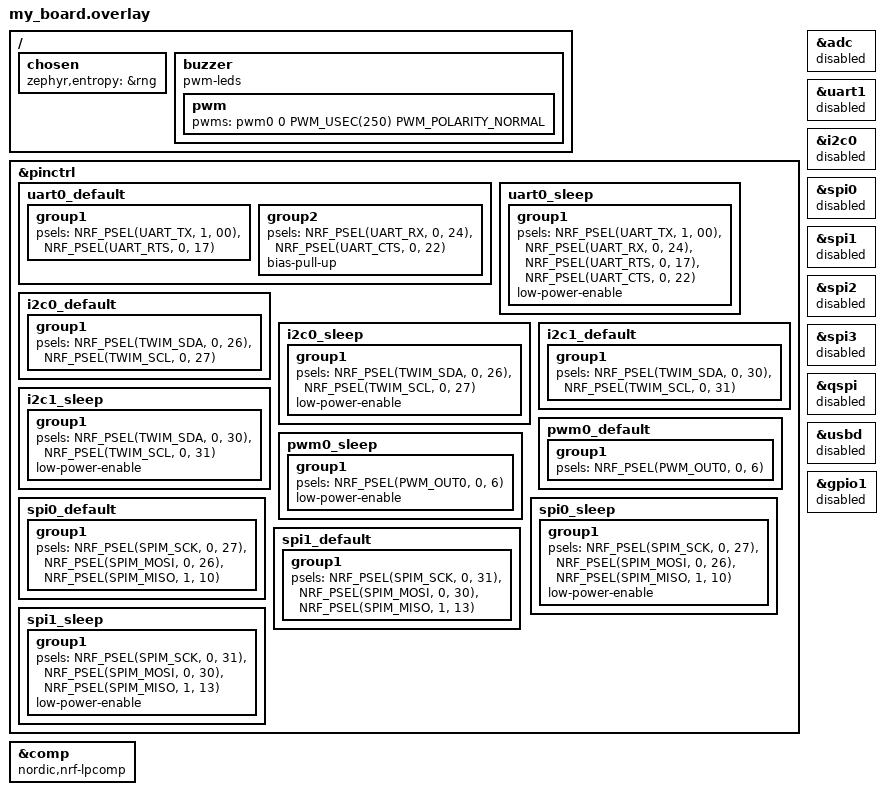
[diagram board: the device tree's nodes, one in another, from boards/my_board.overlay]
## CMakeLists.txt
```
list(APPEND OVERLAY_CONFIG "dns.conf")
list(APPEND OVERLAY_CONFIG "secret.conf")
list(APPEND OVERLAY_CONFIG "thread-sed.conf")

cmake_minimum_required(VERSION 3.20.0)
list(APPEND BOARD_ROOT ${CMAKE_CURRENT_SOURCE_DIR})
find_package(Zephyr REQUIRED HINTS $ENV{ZEPHYR_BASE})

execute_process(COMMAND git describe
                WORKING_DIRECTORY ${CMAKE_CURRENT_SOURCE_DIR}
                OUTPUT_VARIABLE GIT_DESCRIBE
                ERROR_QUIET)
string(STRIP "${GIT_DESCRIBE}" GIT_DESCRIBE)
STRING(REGEX MATCH "[0-9]+\\.[0-9]+\\.[0-9]+"
       VERSION "${GIT_DESCRIBE}")

project(app LANGUAGES C VERSION ${VERSION})


configure_file(app_version.h.in ${CMAKE_BINARY_DIR}/app/include/app_version.h)
zephyr_include_directories(
    ${CMAKE_BINARY_DIR}/app/include
)
target_include_directories(app PRIVATE ${CMAKE_BINARY_DIR}/app/include src)

target_sources(app PRIVATE
        src/buzzer.c
        src/main.c)
```

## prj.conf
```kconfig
CONFIG_HEAP_MEM_POOL_SIZE=2048

CONFIG_PM_DEVICE=y
CONFIG_POWEROFF=y

CONFIG_MY_MODULE_BASE_RESET=y
CONFIG_MY_MODULE_BASE_UID=y

CONFIG_MY_MODULE_BASE_HOME_ASSISTANT=y
CONFIG_MY_MODULE_BASE_HA_DEVICE_NAME="Leak Detector"
CONFIG_MY_MODULE_BASE_HA_DEV_TYPE_LEAK_DETECTOR=y
CONFIG_MY_MODULE_BASE_HA_MQTT_SERVER_HOSTNAME="home.home.arpa"

CONFIG_MAIN_STACK_SIZE=4096
CONFIG_SYSTEM_WORKQUEUE_STACK_SIZE=2048
CONFIG_LOG_BUFFER_SIZE=16384

# This board does not have the inductor.
# Cannot enable the DCDC converter.
CONFIG_BOARD_ENABLE_DCDC=n

CONFIG_THREAD_NAME=y
CONFIG_THREAD_ANALYZER=y

CONFIG_LOG_SPEED=y
CONFIG_LOG=y
```

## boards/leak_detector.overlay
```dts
// &pwm0 {
// 	compatible = "nordic,nrf-pwm-seq";
// 	status = "okay";
// 	pinctrl-0 = <&pwm0_default>;
// 	pinctrl-1 = <&pwm0_sleep>;
// 	pinctrl-names = "default", "sleep";
// };
```

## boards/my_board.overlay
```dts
/* Copyright (c) 2020 Nordic Semiconductor ASA
 *
 * SPDX-License-Identifier: LicenseRef-Nordic-5-Clause
 */

/ {
	/*
	* In some default configurations within the nRF Connect SDK,
	* e.g. on nRF52840, the chosen zephyr,entropy node is &cryptocell.
	* This devicetree overlay ensures that default is overridden wherever it
	* is set, as this application uses the RNG node for entropy exclusively.
	*/
	chosen {
		zephyr,entropy = &rng;
	};
	buzzer {
		compatible = "pwm-leds";
		pwm {
			pwms = <&pwm0 0 PWM_USEC(250) PWM_POLARITY_NORMAL>;
		};
	};
};
&pinctrl {
	uart0_default: uart0_default {
		group1 {
			psels = <NRF_PSEL(UART_TX, 1, 00)>,
				<NRF_PSEL(UART_RTS, 0, 17)>;
		};
		group2 {
			psels = <NRF_PSEL(UART_RX, 0, 24)>,
				<NRF_PSEL(UART_CTS, 0, 22)>;
			bias-pull-up;
		};
	};

	uart0_sleep: uart0_sleep {
		group1 {
			psels = <NRF_PSEL(UART_TX, 1, 00)>,
				<NRF_PSEL(UART_RX, 0, 24)>,
				<NRF_PSEL(UART_RTS, 0, 17)>,
				<NRF_PSEL(UART_CTS, 0, 22)>;
			low-power-enable;
		};
	};

	i2c0_default: i2c0_default {
		group1 {
			psels = <NRF_PSEL(TWIM_SDA, 0, 26)>,
				<NRF_PSEL(TWIM_SCL, 0, 27)>;
		};
	};

	i2c0_sleep: i2c0_sleep {
		group1 {
			psels = <NRF_PSEL(TWIM_SDA, 0, 26)>,
				<NRF_PSEL(TWIM_SCL, 0, 27)>;
			low-power-enable;
		};
	};

	i2c1_default: i2c1_default {
		group1 {
			psels = <NRF_PSEL(TWIM_SDA, 0, 30)>,
				<NRF_PSEL(TWIM_SCL, 0, 31)>;
		};
	};

	i2c1_sleep: i2c1_sleep {
		group1 {
			psels = <NRF_PSEL(TWIM_SDA, 0, 30)>,
				<NRF_PSEL(TWIM_SCL, 0, 31)>;
			low-power-enable;
		};
	};

	pwm0_default: pwm0_default {
		group1 {
			psels = <NRF_PSEL(PWM_OUT0, 0, 6)>;
		};
	};

	pwm0_sleep: pwm0_sleep {
		group1 {
			psels = <NRF_PSEL(PWM_OUT0, 0, 6)>;
			low-power-enable;
		};
	};

	spi0_default: spi0_default {
		group1 {
			psels = <NRF_PSEL(SPIM_SCK, 0, 27)>,
				<NRF_PSEL(SPIM_MOSI, 0, 26)>,
				<NRF_PSEL(SPIM_MISO, 1, 10)>;
		};
	};

	spi0_sleep: spi0_sleep {
		group1 {
			psels = <NRF_PSEL(SPIM_SCK, 0, 27)>,
				<NRF_PSEL(SPIM_MOSI, 0, 26)>,
				<NRF_PSEL(SPIM_MISO, 1, 10)>;
			low-power-enable;
		};
	};

	spi1_default: spi1_default {
		group1 {
			psels = <NRF_PSEL(SPIM_SCK, 0, 31)>,
				<NRF_PSEL(SPIM_MOSI, 0, 30)>,
				<NRF_PSEL(SPIM_MISO, 1, 13)>;
		};
	};

	spi1_sleep: spi1_sleep {
		group1 {
			psels = <NRF_PSEL(SPIM_SCK, 0, 31)>,
				<NRF_PSEL(SPIM_MOSI, 0, 30)>,
				<NRF_PSEL(SPIM_MISO, 1, 13)>;
			low-power-enable;
		};
	};

};
&adc {
	status = "disabled";
};
&comp {
	compatible = "nordic,nrf-lpcomp";
	status = "okay";
};
&uart1 {
	status = "disabled";
};
//&pwm0 {
//	status = "disabled";
//};
&i2c0 {
	status = "disabled";
};
&spi0 {
	status = "disabled";
};
&spi1 {
	status = "disabled";
};
&spi2 {
	status = "disabled";
};
&spi3 {
	status = "disabled";
};
&qspi {
	status = "disabled";
};
&usbd {
	status = "disabled";
};
&gpio1 {
	status = "disabled";
};
```

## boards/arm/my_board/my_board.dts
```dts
/*
 * Copyright (c) 2018 Nordic Semiconductor ASA
 * Copyright (c) 2017 Linaro Limited
 *
 * SPDX-License-Identifier: Apache-2.0
 */

/dts-v1/;
#include <nordic/nrf52840_qiaa.dtsi>
#include "my_board-pinctrl.dtsi"

/ {
	model = "My Board";
	compatible = "gervais,my-board";

	chosen {
		zephyr,console = &uart0;
		zephyr,shell-uart = &uart0;
		zephyr,uart-mcumgr = &uart0;
		zephyr,bt-mon-uart = &uart0;
		zephyr,bt-c2h-uart = &uart0;
		zephyr,sram = &sram0;
		zephyr,flash = &flash0;
		zephyr,code-partition = &slot0_partition;
	};

	// leds {
	// 	compatible = "gpio-leds";
	// 	led0_green: led_0 {
	// 		gpios = <&gpio0 6 GPIO_ACTIVE_LOW>;
	// 		label = "Green LED 0";
	// 	};
	// 	led1_red: led_1 {
	// 		gpios = <&gpio0 8 GPIO_ACTIVE_LOW>;
	// 		label = "Red LED 1";
	// 	};
	// 	led1_green: led_2 {
	// 		gpios = <&gpio1 9 GPIO_ACTIVE_LOW>;
	// 		label = "Green LED 1";
	// 	};
	// 	led1_blue: led_3 {
	// 		gpios = <&gpio0 12 GPIO_ACTIVE_LOW>;
	// 		label = "Blue LED 1";
	// 	};
	// };

	// pwmleds {
	// 	compatible = "pwm-leds";
	// 	red_pwm_led: pwm_led_0 {
	// 		pwms = <&pwm0 0 PWM_MSEC(20) PWM_POLARITY_INVERTED>;
	// 	};
	// 	green_pwm_led: pwm_led_1 {
	// 		pwms = <&pwm0 1 PWM_MSEC(20) PWM_POLARITY_INVERTED>;
	// 	};
	// 	blue_pwm_led: pwm_led_2 {
	// 		pwms = <&pwm0 2 PWM_MSEC(20) PWM_POLARITY_INVERTED>;
	// 	};
	// };

	// buttons {
	// 	compatible = "gpio-keys";
	// 	button0: button_0 {
	// 		gpios = <&gpio1 6 (GPIO_PULL_UP | GPIO_ACTIVE_LOW)>;
	// 		label = "Push button switch 0";
	// 	};
	// };

	/* These aliases are provided for compatibility with samples */
	aliases {
		// sw0 = &button0;
		// led0 = &led0_green;
		// led1 = &led1_red;
		// led2 = &led1_green;
		// led3 = &led1_blue;
		// led0-green = &led0_green;
		// led1-red   = &led1_red;
		// led1-green = &led1_green;
		// led1-blue  = &led1_blue;
		// pwm-led0 = &red_pwm_led;
		// pwm-led1 = &green_pwm_led;
		// pwm-led2 = &blue_pwm_led;
		// red-pwm-led = &red_pwm_led;
		// green-pwm-led = &green_pwm_led;
		// blue-pwm-led = &blue_pwm_led;
		// mcuboot-button0 = &button0;
		// mcuboot-led0 = &led0_green;
		watchdog0 = &wdt0;
	};
};

&adc {
	status = "okay";
};

&gpiote {
	status = "okay";
};

&gpio0 {
	status = "okay";
};

&gpio1 {
	status = "okay";
};

&uart0 {
	compatible = "nordic,nrf-uarte";
	status = "okay";
	current-speed = <115200>;
	pinctrl-0 = <&uart0_default>;
	pinctrl-1 = <&uart0_sleep>;
	pinctrl-names = "default", "sleep";
};

&i2c0 {
	compatible = "nordic,nrf-twi";
	status = "okay";
	pinctrl-0 = <&i2c0_default>;
	pinctrl-1 = <&i2c0_sleep>;
	pinctrl-names = "default", "sleep";
};

&i2c1 {
	compatible = "nordic,nrf-twi";
	/* Cannot be used together with spi1. */
	/* status = "okay"; */
	pinctrl-0 = <&i2c1_default>;
	pinctrl-1 = <&i2c1_sleep>;
	pinctrl-names = "default", "sleep";
};

&pwm0 {
	status = "okay";
	pinctrl-0 = <&pwm0_default>;
	pinctrl-1 = <&pwm0_sleep>;
	pinctrl-names = "default", "sleep";
};

/*
 * By default, not adding all available SPI instances (spi2, spi3) due to
 * limited GPIOs available on dongle board.
 */
&spi0 {
	compatible = "nordic,nrf-spi";
	/* Cannot be used together with i2c0. */
	/* status = "okay"; */
	pinctrl-0 = <&spi0_default>;
	pinctrl-1 = <&spi0_sleep>;
	pinctrl-names = "default", "sleep";
};

&spi1 {
	compatible = "nordic,nrf-spi";
	status = "okay";
	pinctrl-0 = <&spi1_default>;
	pinctrl-1 = <&spi1_sleep>;
	pinctrl-names = "default", "sleep";
};

/* Include flash partition table.
 * Two partition tables are available:
 * fstab-stock		-compatible with Nordic nRF5 bootloader, default
 * fstab-debugger	-to use an external debugger, w/o the nRF5 bootloader
 */
#include "fstab-debugger.dts"

zephyr_udc0: &usbd {
	compatible = "nordic,nrf-usbd";
	status = "okay";
};
```

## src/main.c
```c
#include <zephyr/drivers/pwm.h>
#include <zephyr/kernel.h>
#include <zephyr/pm/device.h>
#include <zephyr/pm/pm.h>
#include <zephyr/pm/policy.h>
#include <zephyr/sys/poweroff.h>

#include <hal/nrf_power.h>
#include <nrfx_lpcomp.h>

#include <zephyr/logging/log.h>
LOG_MODULE_REGISTER(main, LOG_LEVEL_DBG);

#include <app_version.h>
#include <mymodule/base/ha.h>
#include <mymodule/base/mqtt.h>
#include <mymodule/base/openthread.h>
#include <mymodule/base/reset.h>
#include <mymodule/base/uid.h>

#include "buzzer.h"


#define ALARM_TIME_SEC		60
#define HA_NUMBER_OF_RETRIES	3
#define HA_RETRY_DELAY_SECONDS	10


static struct ha_sensor leak_detected_sensor = {
	.type = HA_BINARY_SENSOR_TYPE,
	.name = "Leak",
	.device_class = "problem",
	.retain = true,
};


static void comparator_handler(nrf_lpcomp_event_t event)
{
	LOG_INF("COMP event");
}

static int system_off(void)
{
	int ret;
	const struct device *cons = DEVICE_DT_GET(DT_CHOSEN(zephyr_console));

	LOG_INF("Entering system off");

	ret = pm_device_action_run(cons, PM_DEVICE_ACTION_SUSPEND);
	if (ret < 0) {
		LOG_ERR("Could not suspend console (%d)", ret);
		return -1;
	}

	sys_poweroff();

	return 0;
}

int main(void)
{
	uint32_t reset_cause;
	int ret;

	nrfx_err_t err;
	nrfx_lpcomp_config_t lpcomp_config = {
	    .reference = NRF_LPCOMP_REF_SUPPLY_6_8,
	    .detection = NRF_LPCOMP_DETECT_DOWN,
	    NRFX_COND_CODE_1(LPCOMP_FEATURE_HYST_PRESENT, (.hyst = NRF_LPCOMP_HYST_NOHYST,), ())
	    .input  = (nrf_lpcomp_input_t)NRF_LPCOMP_INPUT_2,
	    .interrupt_priority = NRFX_LPCOMP_DEFAULT_CONFIG_IRQ_PRIORITY
	};
	const struct pwm_dt_spec buzzer_dt_spec = PWM_DT_SPEC_GET(DT_PATH(buzzer));


	LOG_INF("\n\n🚀 MAIN START (%s) 🚀\n", APP_VERSION_FULL);

	reset_cause = show_and_clear_reset_cause();

	if (!device_is_ready(buzzer_dt_spec.dev)) {
		printk("%s: device not ready.\n", buzzer_dt_spec.dev->name);
		return 1;
	}

	ret = buzzer_init(&buzzer_dt_spec);
	if (ret < 0) {
		LOG_ERR("Could not initialize buzzer");
		return 1;
	}

	// Do only the bare minimum to start the alarm if required.
	// This is the priority.
	if (is_reset_cause_lpcomp(reset_cause)) {
		buzzer_alarm(ALARM_TIME_SEC);
	}

	ret = openthread_my_start();
	if (ret < 0) {
		LOG_ERR("Could not start openthread");
		return ret;
	}

	ret = uid_init();
	if (ret < 0) {
		LOG_ERR("Could not init uid module");
		return ret;
	}

	ret = uid_generate_unique_id(leak_detected_sensor.unique_id,
				     sizeof(leak_detected_sensor.unique_id),
				     "nrf52840", "leak",
				     uid_get_device_id());
	if (ret < 0) {
		LOG_ERR("Could not generate leak sensor unique id");
		return ret;
	}

	LOG_INF("💤 waiting for openthread to be ready");
	openthread_wait_for_ready();
	// Something else is not ready, not sure what
	k_sleep(K_MSEC(100));

	bool inhibit_discovery = is_reset_cause_lpcomp(reset_cause);
	bool enable_last_will = false;
	ha_start(uid_get_device_id(), inhibit_discovery, enable_last_will);

	// On the alert path, this has not way to fail other than ENOMEM
	ha_register_sensor_retry(&leak_detected_sensor,
				 HA_NUMBER_OF_RETRIES,
				 HA_RETRY_DELAY_SECONDS,
				 0);

	ha_set_binary_sensor_state(&leak_detected_sensor,
				   is_reset_cause_lpcomp(reset_cause));

	if (is_reset_cause_lpcomp(reset_cause)) {
		// Retry for about 3h, this is the last thing we will do anyway
		ha_send_binary_sensor_retry(&leak_detected_sensor,
				    	    11, // Last after about 3h
					    HA_RETRY_DELAY_SECONDS,
					    (HA_RETRY_EXP_BACKOFF |
					     HA_RETRY_WAIT_PUBACK));
	}
	else {
		// We set the device online a little after sensor
		// registrations so HA gets time to process the sensor
		// registrations first before setting the entities online
		LOG_INF("💤 waiting for HA to process registration");
		k_sleep(K_SECONDS(3));

		ha_set_online_retry(HA_NUMBER_OF_RETRIES,
				    HA_RETRY_DELAY_SECONDS,
				    HA_RETRY_NO_FLAGS);

		ha_send_binary_sensor_retry(&leak_detected_sensor,
				    	    HA_NUMBER_OF_RETRIES,
					    HA_RETRY_DELAY_SECONDS,
					    HA_RETRY_NO_FLAGS);

		// Arm the detector
		err = nrfx_lpcomp_init(&lpcomp_config, comparator_handler);
		if (err != NRFX_SUCCESS) {
			LOG_ERR("nrfx_comp_init error: %08x", err);
			return 1;
		}

		IRQ_CONNECT(COMP_LPCOMP_IRQn,
			    IRQ_PRIO_LOWEST,
			    nrfx_isr, nrfx_lpcomp_irq_handler, 0);

		nrfx_lpcomp_enable();

		LOG_INF("🆗 initialized");

		LOG_INF("Playing detector ready sound");
		// smb3_sound_1up();
		smb3_sound_enter_world();
		// smd3_sound_game_over();
		// smb2_sound_game_over();
		// smb2_main_theme();
	}

	while (buzzer_is_running(&buzzer_dt_spec)) {
		LOG_INF("Waiting for buzzer to finish");
		k_sleep(K_SECONDS(1));
	}

	system_off();

	return 0;
}
```

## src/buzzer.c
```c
#include <zephyr/drivers/pwm.h>
#include <zephyr/kernel.h>

#include <zephyr/logging/log.h>
// LOG_MODULE_REGISTER(buzzer, LOG_LEVEL_DBG);
LOG_MODULE_REGISTER(buzzer, LOG_LEVEL_INF);

#include <nrfx_pwm.h>

#include "music_notes.h"


#define ALARM_PWM_BASE_CLOCK	16000000.0f
#define ALARM_PWM_PRESCALER	1.0f
#define ALARM_PWM_CLOCK_HZ	(ALARM_PWM_BASE_CLOCK / ALARM_PWM_PRESCALER)

#define ALARM_DESIRED_FREQ_HZ	4000.0f
#define ALARM_TOP_VALUE		((1.0f/ALARM_DESIRED_FREQ_HZ) / (1.0f/ALARM_PWM_CLOCK_HZ))

#define ALARM_PERIOD_SEC 	0.500f
#define ALARM_VALUE_REPEAT	((ALARM_PERIOD_SEC / 2.0f) / (1.0f/ALARM_DESIRED_FREQ_HZ))

#define MAX_NUMBER_OF_NOTES	32


/*
 * Although we send a sequence of a single note at a time, `note_value[]` is of
 * size `2` because the STOP event is triggered when the last value of the
 * sequence is loaded i.e. before the value is repeated.
 * Without this second dummy value, only the first period of the note would be
 * played.
 * 
 * See `NRFX_PWM_FLAG_STOP` definition for more information.
 * 
 * > The STOP task is triggered when the last value of the final sequence is
 * loaded from RAM, and the peripheral stops at the end of the current PWM period.
 * For sequences with configured repeating of duty cycle values, this might
 * result in less than the requested number of repeats of the last value.
 */
struct sound_effect_playback {
	uint16_t note_value[2];
	uint16_t notes_base_clock[MAX_NUMBER_OF_NOTES];
	uint16_t notes_top_value[MAX_NUMBER_OF_NOTES];
	uint16_t notes_value[MAX_NUMBER_OF_NOTES];
	uint32_t notes_repeat_value[MAX_NUMBER_OF_NOTES];
	int number_of_notes;
	int note_to_play;
};

enum mode {
	ALARM,
	SOUND_EFFECT,
};

struct buzzer {
	nrfx_pwm_t *pwm_instance;
	enum mode mode;
	struct sound_effect_playback sep;
	uint16_t alarm_sequence_values[2];
};


static void play_next_note(struct buzzer *buzzer);


static void pwm_handler(nrfx_pwm_evt_type_t event_type, void *p_context)
{
	struct buzzer *buzzer = p_context;
	struct sound_effect_playback *sep = &buzzer->sep;

	LOG_DBG("pwm_handler (%d)", event_type);

	if (event_type == NRFX_PWM_EVT_STOPPED) {
		if (buzzer->mode == SOUND_EFFECT
		    && sep->note_to_play < sep->number_of_notes) {
			play_next_note(buzzer);
		}
	}
}


static struct buzzer buzzer  = {
	.alarm_sequence_values = {
		ALARM_TOP_VALUE / 2,	// 50% PWM
		ALARM_TOP_VALUE,	// 0%
	},
};


static int add_note(struct sound_effect_playback *sep,
		     float note, float note_duration_ms)
{
	int note_index = sep->number_of_notes;
	uint8_t clk_divider;
	uint32_t top_value; // 32bit so we can verify if is fits in 15bit
	uint32_t pwm_clock;

	LOG_DBG("-----------------");

	LOG_DBG("note: %d", (int)note);

	if (note == 0) {
		pwm_clock = 16000000;
		clk_divider = 0;
		top_value = 16000; // Gives 1ms per pwm period
	}
	else {
		for (clk_divider = 0; clk_divider < 8; clk_divider++) {
			pwm_clock = 16000000 >> clk_divider;
			LOG_DBG("pwm_clock: %d", pwm_clock);

			top_value = (1.0f / note) / (1.0f / pwm_clock);
			LOG_DBG("top_value: %d", top_value);

			if (top_value < (UINT16_MAX >> 1)) {
				break;
			}
		}

		if (clk_divider == 8) {
			LOG_ERR("Could not find a suitable PWM divider");
			return -EINVAL;
		}
	}

	sep->notes_base_clock[note_index] = clk_divider;
	sep->notes_top_value[note_index] = top_value;

	if (note == 0) {
		sep->notes_value[note_index] = top_value;
	}
	else {
		sep->notes_value[note_index] = top_value / 2.0f;
	}

	sep->notes_repeat_value[note_index] = (
		(note_duration_ms / 1000.0f)
		/ ((1.0f / pwm_clock) * top_value)
	);

	LOG_DBG("notes_repeat_value: %d", sep->notes_repeat_value[note_index]);

	sep->number_of_notes++;

	return 0;
}

static void play_next_note(struct buzzer *buzzer)
{
	struct sound_effect_playback *sep = &buzzer->sep;

	LOG_DBG("🎹 Playing note %d", sep->note_to_play);
	LOG_DBG("├── note base clock %d", sep->notes_base_clock[sep->note_to_play]);
	LOG_DBG("├── note top value %d", sep->notes_top_value[sep->note_to_play]);
	LOG_DBG("├── note value %d", sep->notes_value[sep->note_to_play]);
	LOG_DBG("└── note repeat %d", sep->notes_repeat_value[sep->note_to_play]);

	sep->note_value[0] = sep->notes_value[sep->note_to_play];

	nrf_pwm_configure(buzzer->pwm_instance->p_reg,
			  sep->notes_base_clock[sep->note_to_play],
			  NRF_PWM_MODE_UP,
			  sep->notes_top_value[sep->note_to_play]);

	nrf_pwm_sequence_t note_sequence = {
		.values.p_raw = (uint16_t *)&sep->note_value,
		.length = ARRAY_SIZE(sep->note_value),
		.repeats = sep->notes_repeat_value[sep->note_to_play],
	};

	nrfx_pwm_simple_playback(buzzer->pwm_instance,
				 &note_sequence,
				 1,
				 NRFX_PWM_FLAG_STOP);

	sep->note_to_play++;
}

void smb3_sound_1up(void)
{
	buzzer.mode = SOUND_EFFECT;

	buzzer.sep.note_to_play = 0;
	buzzer.sep.number_of_notes = 0;

	add_note(&buzzer.sep, NOTE_E6, 135);
	add_note(&buzzer.sep, NOTE_G6, 135);
	add_note(&buzzer.sep, NOTE_E7, 135);
	add_note(&buzzer.sep, NOTE_C7, 135);
	add_note(&buzzer.sep, NOTE_D7, 135);
	add_note(&buzzer.sep, NOTE_G7, 135);

	play_next_note(&buzzer);
}

void smb3_sound_enter_world(void)
{
	buzzer.mode = SOUND_EFFECT;

	buzzer.sep.note_to_play = 0;
	buzzer.sep.number_of_notes = 0;

	add_note(&buzzer.sep, NOTE_FS8, 66);
	add_note(&buzzer.sep, NOTE_DS8, 66);
	add_note(&buzzer.sep, NOTE_C8, 66);
	add_note(&buzzer.sep, NOTE_A7, 66);
	add_note(&buzzer.sep, NOTE_G7, 66);
	add_note(&buzzer.sep, NOTE_E7, 66);
	add_note(&buzzer.sep, NOTE_CS7, 66);
	add_note(&buzzer.sep, NOTE_A6, 66);
	add_note(&buzzer.sep, NOTE_G6, 66);
	add_note(&buzzer.sep, NOTE_E6, 66);
	add_note(&buzzer.sep, NOTE_CS6, 66);
	add_note(&buzzer.sep, NOTE_A5, 300);

	play_next_note(&buzzer);
}

void smd3_sound_game_over(void)
{
	buzzer.mode = SOUND_EFFECT;

	buzzer.sep.note_to_play = 0;
	buzzer.sep.number_of_notes = 0;

	add_note(&buzzer.sep, NOTE_G5, 150);
	add_note(&buzzer.sep, 0, 50);
	add_note(&buzzer.sep, NOTE_G5, 150);
	add_note(&buzzer.sep, 0, 50);
	add_note(&buzzer.sep, NOTE_G5, 150);
	add_note(&buzzer.sep, 0, 50);
	add_note(&buzzer.sep, NOTE_D6, 400);
	add_note(&buzzer.sep, NOTE_C6, 200);
	add_note(&buzzer.sep, NOTE_A5, 200);
	add_note(&buzzer.sep, NOTE_F5, 200);
	add_note(&buzzer.sep, NOTE_AS5, 200);
	add_note(&buzzer.sep, 0, 400);
	add_note(&buzzer.sep, NOTE_CS5, 200);
	add_note(&buzzer.sep, NOTE_D5, 150);
	add_note(&buzzer.sep, 0, 50);
	add_note(&buzzer.sep, NOTE_G4, 200);

	play_next_note(&buzzer);
}

void smb2_sound_game_over(void)
{
	buzzer.mode = SOUND_EFFECT;

	buzzer.sep.note_to_play = 0;
	buzzer.sep.number_of_notes = 0;

	add_note(&buzzer.sep, NOTE_G6, 100);
	add_note(&buzzer.sep, NOTE_A6, 100);
	add_note(&buzzer.sep, NOTE_C7, 100);
	add_note(&buzzer.sep, 0, 50);
	add_note(&buzzer.sep, NOTE_G5, 100);
	add_note(&buzzer.sep, NOTE_A5, 100);
	add_note(&buzzer.sep, NOTE_C6, 100);
	add_note(&buzzer.sep, 0, 50);
	add_note(&buzzer.sep, NOTE_G4, 100);
	add_note(&buzzer.sep, NOTE_A4, 100);
	add_note(&buzzer.sep, NOTE_C5, 100);
	add_note(&buzzer.sep, 0, 100);
	add_note(&buzzer.sep, NOTE_F4, 100);
	add_note(&buzzer.sep, 0, 100);
	add_note(&buzzer.sep, NOTE_E4, 150);

	play_next_note(&buzzer);
}

void smb2_main_theme(void)
{
	buzzer.mode = SOUND_EFFECT;

	buzzer.sep.note_to_play = 0;
	buzzer.sep.number_of_notes = 0;

	add_note(&buzzer.sep, NOTE_G6, 100);
	add_note(&buzzer.sep, NOTE_FS6, 100);
	add_note(&buzzer.sep, 0, 50);
	add_note(&buzzer.sep, NOTE_F6, 100);
	add_note(&buzzer.sep, NOTE_D6, 100);
	add_note(&buzzer.sep, 0, 50);
	add_note(&buzzer.sep, NOTE_B5, 100);
	add_note(&buzzer.sep, NOTE_A5, 100);
	add_note(&buzzer.sep, 0, 50);
	add_note(&buzzer.sep, NOTE_GS5, 100);
	add_note(&buzzer.sep, NOTE_G5, 100);
	add_note(&buzzer.sep, 0, 150);
	add_note(&buzzer.sep, NOTE_G6, 100);
	add_note(&buzzer.sep, 0, 200);
	add_note(&buzzer.sep, NOTE_G5, 200);

	play_next_note(&buzzer);
}

int buzzer_alarm(int seconds)
{
	buzzer.mode = ALARM;

	nrf_pwm_configure(buzzer.pwm_instance->p_reg,
			  LOG2(ALARM_PWM_PRESCALER) / LOG2(2),
			  NRF_PWM_MODE_UP,
			  ALARM_TOP_VALUE);

	nrf_pwm_sequence_t alarm_sequence = {
		.values.p_raw = buzzer.alarm_sequence_values,
		.length = ARRAY_SIZE(buzzer.alarm_sequence_values),
		.repeats = ALARM_VALUE_REPEAT,
	};

	nrfx_pwm_simple_playback(buzzer.pwm_instance,
				 &alarm_sequence,
				 seconds / ALARM_PERIOD_SEC,
				 NRFX_PWM_FLAG_STOP);

	return 0;
}

bool buzzer_is_running(const struct pwm_dt_spec *buzzer)
{
	const nrfx_pwm_t *pwm_instance = buzzer->dev->config;

	return !nrfx_pwm_stopped_check(pwm_instance);
}

int buzzer_init(const struct pwm_dt_spec *spec)
{
	int ret;

	nrfx_pwm_config_t pwm_initial_config = {					      \
		.skip_gpio_cfg = true,
		.skip_psel_cfg = true,
		.base_clock = NRF_PWM_CLK_16MHz,
		.count_mode = NRF_PWM_MODE_UP,
		.top_value = 0,
		.load_mode = NRF_PWM_LOAD_COMMON,
		.step_mode = NRF_PWM_STEP_AUTO,
	};

	// We cheat here but we can do it since `nrfx_pwm_t`
	// is the first member of the struct.
	const nrfx_pwm_t *pwm_instance = spec->dev->config;

	buzzer.pwm_instance =(nrfx_pwm_t *)pwm_instance;

	nrfx_pwm_uninit(pwm_instance);

	ret = nrfx_pwm_init(pwm_instance, &pwm_initial_config,
                        	 pwm_handler, &buzzer);
	if (ret != NRFX_SUCCESS) {
		LOG_ERR("Cannot initialize pwm");
		return -EIO;
	}

	IRQ_CONNECT(DT_IRQN(DT_NODELABEL(pwm0)),
		    DT_IRQ(DT_NODELABEL(pwm0), priority),
		    nrfx_isr, NRFX_PWM_INST_HANDLER_GET(0), 0);

	return 0;
}
```

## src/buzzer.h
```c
#ifndef BUZZER_H_
#define BUZZER_H_

struct pwm_dt_spec;

void smb3_sound_1up(void);
void smb3_sound_enter_world(void);
void smd3_sound_game_over(void);
void smb2_sound_game_over(void);
void smb2_main_theme(void);

int buzzer_alarm(int seconds);
bool buzzer_is_running(const struct pwm_dt_spec *spec);
int buzzer_init(const struct pwm_dt_spec *spec);

#endif /* BUZZER_H_ */
```

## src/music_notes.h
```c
#define NOTE_B0  31
#define NOTE_C1  33
#define NOTE_CS1 35
#define NOTE_D1  37
#define NOTE_DS1 39
#define NOTE_E1  41
#define NOTE_F1  44
#define NOTE_FS1 46
#define NOTE_G1  49
#define NOTE_GS1 52
#define NOTE_A1  55
#define NOTE_AS1 58
#define NOTE_B1  62
#define NOTE_C2  65
#define NOTE_CS2 69
#define NOTE_D2  73
#define NOTE_DS2 78
#define NOTE_E2  82
#define NOTE_F2  87
#define NOTE_FS2 93
#define NOTE_G2  98
#define NOTE_GS2 104
#define NOTE_A2  110
#define NOTE_AS2 117
#define NOTE_B2  123
#define NOTE_C3  131
#define NOTE_CS3 139
#define NOTE_D3  147
#define NOTE_DS3 156
#define NOTE_E3  165
#define NOTE_F3  175
#define NOTE_FS3 185
#define NOTE_G3  196
#define NOTE_GS3 208
#define NOTE_A3  220
#define NOTE_AS3 233
#define NOTE_B3  247
#define NOTE_C4  262
#define NOTE_CS4 277
#define NOTE_D4  294
#define NOTE_DS4 311
#define NOTE_E4  330
#define NOTE_F4  349
#define NOTE_FS4 370
#define NOTE_G4  392
#define NOTE_GS4 415
#define NOTE_A4  440
#define NOTE_AS4 466
#define NOTE_B4  494
#define NOTE_C5  523
#define NOTE_CS5 554
#define NOTE_D5  587
#define NOTE_DS5 622
#define NOTE_E5  659
#define NOTE_F5  698
#define NOTE_FS5 740
#define NOTE_G5  784
#define NOTE_GS5 831
#define NOTE_A5  880
#define NOTE_AS5 932
#define NOTE_B5  988
#define NOTE_C6  1047
#define NOTE_CS6 1109
#define NOTE_D6  1175
#define NOTE_DS6 1245
#define NOTE_E6  1319
#define NOTE_F6  1397
#define NOTE_FS6 1480
#define NOTE_G6  1568
#define NOTE_GS6 1661
#define NOTE_A6  1760
#define NOTE_AS6 1865
#define NOTE_B6  1976
#define NOTE_C7  2093
#define NOTE_CS7 2217
#define NOTE_D7  2349
#define NOTE_DS7 2489
#define NOTE_E7  2637
#define NOTE_F7  2794
#define NOTE_FS7 2960
#define NOTE_G7  3136
#define NOTE_GS7 3322
#define NOTE_A7  3520
#define NOTE_AS7 3729
#define NOTE_B7  3951
#define NOTE_C8  4186
#define NOTE_CS8 4435
#define NOTE_D8  4699
#define NOTE_DS8 4978
#define NOTE_E8  5274
#define NOTE_F8  5587
#define NOTE_FS8 5919
#define NOTE_G8  6271
#define NOTE_GS8 6644
#define NOTE_A8  7040
#define NOTE_AS8 7458
#define NOTE_B8  7902
```

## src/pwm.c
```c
#include <nrfx_pwm.h>
#include <zephyr/drivers/pwm.h>
#include <zephyr/pm/device.h>
#include <zephyr/drivers/pinctrl.h>
#include <soc.h>
#include <hal/nrf_gpio.h>
#include <stdbool.h>
#include <zephyr/linker/devicetree_regions.h>

#include <zephyr/logging/log.h>

LOG_MODULE_REGISTER(pwm_nrfx, CONFIG_PWM_LOG_LEVEL);

/* NRFX_PWM_NRF52_ANOMALY_109_WORKAROUND_ENABLED can be undefined or defined
 * to 0 or 1, hence the use of #if IS_ENABLED().
 */
#if IS_ENABLED(NRFX_PWM_NRF52_ANOMALY_109_WORKAROUND_ENABLED)
#define ANOMALY_109_IRQ_CONNECT(...) IRQ_CONNECT(__VA_ARGS__)
#define ANOMALY_109_EGU_IRQ_CONNECT(idx) _EGU_IRQ_CONNECT(idx)
#define _EGU_IRQ_CONNECT(idx) \
	extern void nrfx_egu_##idx##_irq_handler(void); \
	IRQ_CONNECT(DT_IRQN(DT_NODELABEL(egu##idx)), \
		    DT_IRQ(DT_NODELABEL(egu##idx), priority), \
		    nrfx_isr, nrfx_egu_##idx##_irq_handler, 0)
#else
#define ANOMALY_109_IRQ_CONNECT(...)
#define ANOMALY_109_EGU_IRQ_CONNECT(idx)
#endif

#define PWM_NRFX_CH_POLARITY_MASK BIT(15)
#define PWM_NRFX_CH_COMPARE_MASK  BIT_MASK(15)
#define PWM_NRFX_CH_VALUE(compare_value, inverted) \
	(compare_value | (inverted ? 0 : PWM_NRFX_CH_POLARITY_MASK))

struct pwm_nrfx_config {
	nrfx_pwm_t pwm;
	nrfx_pwm_config_t initial_config;
	nrf_pwm_sequence_t seq;
	const struct pinctrl_dev_config *pcfg;
};

struct pwm_nrfx_data {
	uint32_t period_cycles;
	/* Bit mask indicating channels that need the PWM generation. */
	uint8_t  pwm_needed;
	uint8_t  prescaler;
	bool     stop_requested;
};
/* Ensure the pwm_needed bit mask can accommodate all available channels. */
#if (NRF_PWM_CHANNEL_COUNT > 8)
#error "Current implementation supports maximum 8 channels."
#endif

static uint16_t *seq_values_ptr_get(const struct device *dev)
{
	const struct pwm_nrfx_config *config = dev->config;

	return (uint16_t *)config->seq.values.p_raw;
}

static bool pwm_period_check_and_set(const struct device *dev,
				     uint32_t channel, uint32_t period_cycles)
{
	const struct pwm_nrfx_config *config = dev->config;
	struct pwm_nrfx_data *data = dev->data;
	uint8_t prescaler;
	uint32_t countertop;

	/* If the currently configured period matches the requested one,
	 * nothing more needs to be done.
	 */
	if (period_cycles == data->period_cycles) {
		return true;
	}

	/* If any other channel is driven by the PWM peripheral, the period
	 * that is currently set cannot be changed, as this would influence
	 * the output for that channel.
	 */
	if ((data->pwm_needed & ~BIT(channel)) != 0) {
		LOG_ERR("Incompatible period.");
		return false;
	}

	/* Try to find a prescaler that will allow setting the requested period
	 * after prescaling as the countertop value for the PWM peripheral.
	 */
	prescaler = 0;
	countertop = period_cycles;
	do {
		if (countertop <= PWM_COUNTERTOP_COUNTERTOP_Msk) {
			data->period_cycles = period_cycles;
			data->prescaler     = prescaler;

			nrf_pwm_configure(config->pwm.p_reg,
					  data->prescaler,
					  config->initial_config.count_mode,
					  (uint16_t)countertop);
			return true;
		}

		countertop >>= 1;
		++prescaler;
	} while (prescaler <= PWM_PRESCALER_PRESCALER_Msk);

	LOG_ERR("Prescaler for period_cycles %u not found.", period_cycles);
	return false;
}

static bool channel_psel_get(uint32_t channel, uint32_t *psel,
			     const struct pwm_nrfx_config *config)
{
	*psel = nrf_pwm_pin_get(config->pwm.p_reg, (uint8_t)channel);

	return (((*psel & PWM_PSEL_OUT_CONNECT_Msk) >> PWM_PSEL_OUT_CONNECT_Pos)
		== PWM_PSEL_OUT_CONNECT_Connected);
}

static int pwm_nrfx_set_cycles(const struct device *dev, uint32_t channel,
			       uint32_t period_cycles, uint32_t pulse_cycles,
			       pwm_flags_t flags)
{
	/* We assume here that period_cycles will always be 16MHz
	 * peripheral clock. Since pwm_nrfx_get_cycles_per_sec() function might
	 * be removed, see ISSUE #6958.
	 * TODO: Remove this comment when issue has been resolved.
	 */
	const struct pwm_nrfx_config *config = dev->config;
	struct pwm_nrfx_data *data = dev->data;
	uint16_t compare_value;
	bool inverted = (flags & PWM_POLARITY_INVERTED);
	bool needs_pwm = false;

	if (channel >= NRF_PWM_CHANNEL_COUNT) {
		LOG_ERR("Invalid channel: %u.", channel);
		return -EINVAL;
	}

	/* If this PWM is in center-aligned mode, pulse and period lengths
	 * are effectively doubled by the up-down count, so halve them here
	 * to compensate.
	 */
	if (config->initial_config.count_mode == NRF_PWM_MODE_UP_AND_DOWN) {
		period_cycles /= 2;
		pulse_cycles /= 2;
	}

	if (pulse_cycles == 0) {
		/* Constantly inactive (duty 0%). */
		compare_value = 0;
	} else if (pulse_cycles >= period_cycles) {
		/* Constantly active (duty 100%). */
		/* This value is always greater than or equal to COUNTERTOP. */
		compare_value = PWM_NRFX_CH_COMPARE_MASK;
	} else {
		/* PWM generation needed. Check if the requested period matches
		 * the one that is currently set, or the PWM peripheral can be
		 * reconfigured accordingly.
		 */
		if (!pwm_period_check_and_set(dev, channel, period_cycles)) {
			return -EINVAL;
		}

		compare_value = (uint16_t)(pulse_cycles >> data->prescaler);
		needs_pwm = true;
	}

	seq_values_ptr_get(dev)[channel] = PWM_NRFX_CH_VALUE(compare_value, inverted);

	LOG_DBG("channel %u, pulse %u, period %u, prescaler: %u.",
		channel, pulse_cycles, period_cycles, data->prescaler);

	/* If this channel does not need to be driven by the PWM peripheral
	 * because its state is to be constant (duty 0% or 100%), set properly
	 * the GPIO configuration for its output pin. This will provide
	 * the correct output state for this channel when the PWM peripheral
	 * is stopped.
	 */
	if (!needs_pwm) {
		uint32_t psel;

		if (channel_psel_get(channel, &psel, config)) {
			uint32_t out_level = (pulse_cycles == 0) ? 0 : 1;

			if (inverted) {
				out_level ^= 1;
			}

			nrf_gpio_pin_write(psel, out_level);
		}

		data->pwm_needed &= ~BIT(channel);
	} else {
		data->pwm_needed |= BIT(channel);
	}

	/* If the PWM generation is not needed for any channel (all are set
	 * to constant inactive or active state), stop the PWM peripheral.
	 * Otherwise, request a playback of the defined sequence so that
	 * the PWM peripheral loads `seq_values` into its internal compare
	 * registers and drives its outputs accordingly.
	 */
	if (data->pwm_needed == 0) {
		/* Don't wait here for the peripheral to actually stop. Instead,
		 * ensure it is stopped before starting the next playback.
		 */
		nrfx_pwm_stop(&config->pwm, false);
		data->stop_requested = true;
	} else {
		if (data->stop_requested) {
			data->stop_requested = false;

			/* After a stop is requested, the PWM peripheral stops
			 * pulse generation at the end of the current period,
			 * and till that moment, it ignores any start requests,
			 * so ensure here that it is stopped.
			 */
			while (!nrfx_pwm_stopped_check(&config->pwm)) {
			}
		}

		/* It is sufficient to play the sequence once without looping.
		 * The PWM generation will continue with the loaded values
		 * until another playback is requested (new values will be
		 * loaded then) or the PWM peripheral is stopped.
		 */
		nrfx_pwm_simple_playback(&config->pwm, &config->seq, 1, 0);
	}

	return 0;
}

static int pwm_nrfx_get_cycles_per_sec(const struct device *dev, uint32_t channel,
				       uint64_t *cycles)
{
	/* TODO: Since this function might be removed, we will always return
	 * 16MHz from this function and handle the conversion with prescaler,
	 * etc, in the pin set function. See issue #6958.
	 */
	*cycles = 16ul * 1000ul * 1000ul;

	return 0;
}

static const struct pwm_driver_api pwm_nrfx_drv_api_funcs = {
	.set_cycles = pwm_nrfx_set_cycles,
	.get_cycles_per_sec = pwm_nrfx_get_cycles_per_sec,
};

static int pwm_nrfx_init(const struct device *dev)
{
	const struct pwm_nrfx_config *config = dev->config;
	uint8_t initially_inverted = 0;

	int ret = pinctrl_apply_state(config->pcfg, PINCTRL_STATE_DEFAULT);

	ANOMALY_109_EGU_IRQ_CONNECT(NRFX_PWM_NRF52_ANOMALY_109_EGU_INSTANCE);

	if (ret < 0) {
		return ret;
	}

	for (size_t i = 0; i < NRF_PWM_CHANNEL_COUNT; i++) {
		uint32_t psel;

		if (channel_psel_get(i, &psel, config)) {
			/* Mark channels as inverted according to what initial
			 * state of their outputs has been set by pinctrl (high
			 * idle state means that the channel is inverted).
			 */
			initially_inverted |= nrf_gpio_pin_out_read(psel) ?
					      BIT(i) : 0;
		}
	}

	for (size_t i = 0; i < NRF_PWM_CHANNEL_COUNT; i++) {
		bool inverted = initially_inverted & BIT(i);

		seq_values_ptr_get(dev)[i] = PWM_NRFX_CH_VALUE(0, inverted);
	}

	nrfx_err_t result = nrfx_pwm_init(&config->pwm,
					  &config->initial_config,
					  NULL,
					  NULL);
	if (result != NRFX_SUCCESS) {
		LOG_ERR("Failed to initialize device: %s", dev->name);
		return -EBUSY;
	}

	return 0;
}

#ifdef CONFIG_PM_DEVICE
static void pwm_nrfx_uninit(const struct device *dev)
{
	const struct pwm_nrfx_config *config = dev->config;

	nrfx_pwm_uninit(&config->pwm);

	memset(dev->data, 0, sizeof(struct pwm_nrfx_data));
}

static int pwm_nrfx_pm_action(const struct device *dev,
			      enum pm_device_action action)
{
	const struct pwm_nrfx_config *config = dev->config;
	int ret = 0;

	switch (action) {
	case PM_DEVICE_ACTION_RESUME:
		ret = pinctrl_apply_state(config->pcfg, PINCTRL_STATE_DEFAULT);
		if (ret < 0) {
			return ret;
		}
		ret = pwm_nrfx_init(dev);
		break;

	case PM_DEVICE_ACTION_SUSPEND:
		pwm_nrfx_uninit(dev);

		ret = pinctrl_apply_state(config->pcfg, PINCTRL_STATE_SLEEP);
		if (ret < 0) {
			return ret;
		}
		break;

	default:
		return -ENOTSUP;
	}

	return ret;
}
#else

#define pwm_nrfx_pm_action NULL

#endif /* CONFIG_PM_DEVICE */

#define PWM(dev_idx) DT_NODELABEL(pwm##dev_idx)
#define PWM_PROP(dev_idx, prop) DT_PROP(PWM(dev_idx), prop)
#define PWM_HAS_PROP(idx, prop) DT_NODE_HAS_PROP(PWM(idx), prop)

#define PWM_MEMORY_SECTION(idx)						      \
	COND_CODE_1(PWM_HAS_PROP(idx, memory_regions),			      \
		(__attribute__((__section__(LINKER_DT_NODE_REGION_NAME(	      \
			DT_PHANDLE(PWM(idx), memory_regions)))))),	      \
		())

#define PWM_NRFX_DEVICE(idx)						      \
	NRF_DT_CHECK_NODE_HAS_PINCTRL_SLEEP(PWM(idx));			      \
	static struct pwm_nrfx_data pwm_nrfx_##idx##_data;		      \
	static uint16_t pwm_##idx##_seq_values[NRF_PWM_CHANNEL_COUNT]	      \
			PWM_MEMORY_SECTION(idx);			      \
	PINCTRL_DT_DEFINE(PWM(idx));					      \
	static const struct pwm_nrfx_config pwm_nrfx_##idx##_config = {	      \
		.pwm = NRFX_PWM_INSTANCE(idx),				      \
		.initial_config = {					      \
			.skip_gpio_cfg = true,				      \
			.skip_psel_cfg = true,				      \
			.base_clock = NRF_PWM_CLK_16MHz,			      \
			.count_mode = (PWM_PROP(idx, center_aligned)	      \
				       ? NRF_PWM_MODE_UP_AND_DOWN	      \
				       : NRF_PWM_MODE_UP),		      \
			.top_value = 4000,				      \
			.load_mode = NRF_PWM_LOAD_INDIVIDUAL,		      \
			.step_mode = NRF_PWM_STEP_TRIGGERED,		      \
		},							      \
		.seq.values.p_raw = pwm_##idx##_seq_values,		      \
		.seq.length = NRF_PWM_CHANNEL_COUNT,			      \
		.pcfg = PINCTRL_DT_DEV_CONFIG_GET(PWM(idx)),		      \
	};								      \
	static int pwm_nrfx_init##idx(const struct device *dev)		      \
	{								      \
		ANOMALY_109_IRQ_CONNECT(				      \
			DT_IRQN(PWM(idx)), DT_IRQ(PWM(idx), priority),	      \
			nrfx_isr, nrfx_pwm_##idx##_irq_handler, 0);	      \
		return pwm_nrfx_init(dev);				      \
	};								      \
	PM_DEVICE_DT_DEFINE(PWM(idx), pwm_nrfx_pm_action);		      \
	DEVICE_DT_DEFINE(PWM(idx),					      \
			 pwm_nrfx_init##idx, PM_DEVICE_DT_GET(PWM(idx)),      \
			 &pwm_nrfx_##idx##_data,			      \
			 &pwm_nrfx_##idx##_config,			      \
			 POST_KERNEL, CONFIG_PWM_INIT_PRIORITY,		      \
			 &pwm_nrfx_drv_api_funcs)

#ifdef CONFIG_HAS_HW_NRF_PWM0
PWM_NRFX_DEVICE(0);
#endif

#ifdef CONFIG_HAS_HW_NRF_PWM1
PWM_NRFX_DEVICE(1);
#endif

#ifdef CONFIG_HAS_HW_NRF_PWM2
PWM_NRFX_DEVICE(2);
#endif

#ifdef CONFIG_HAS_HW_NRF_PWM3
PWM_NRFX_DEVICE(3);
#endif

#ifdef CONFIG_HAS_HW_NRF_PWM20
PWM_NRFX_DEVICE(20);
#endif

#ifdef CONFIG_HAS_HW_NRF_PWM21
PWM_NRFX_DEVICE(21);
#endif

#ifdef CONFIG_HAS_HW_NRF_PWM22
PWM_NRFX_DEVICE(22);
#endif

#ifdef CONFIG_HAS_HW_NRF_PWM120
PWM_NRFX_DEVICE(120);
#endif

#ifdef CONFIG_HAS_HW_NRF_PWM130
PWM_NRFX_DEVICE(130);
#endif

#ifdef CONFIG_HAS_HW_NRF_PWM131
PWM_NRFX_DEVICE(131);
#endif

#ifdef CONFIG_HAS_HW_NRF_PWM132
PWM_NRFX_DEVICE(132);
#endif

#ifdef CONFIG_HAS_HW_NRF_PWM133
PWM_NRFX_DEVICE(133);
#endif
```
